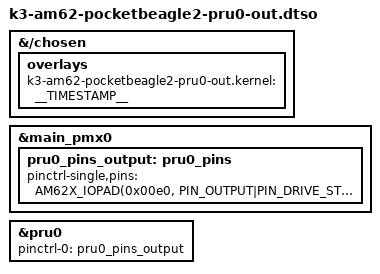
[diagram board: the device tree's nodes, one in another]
// SPDX-License-Identifier: GPL-2.0-only OR MIT
/*
 * Copyright (C) 2026 David Summers
 */
/dts-v1/;
/plugin/;

#include <dt-bindings/gpio/gpio.h>
#include "k3-pinctrl.h"

/*
 * Helper to show loaded overlays under: /proc/device-tree/chosen/overlays/
 */
&{/chosen} {
	overlays {
		k3-am62-pocketbeagle2-pru0-out.kernel = __TIMESTAMP__;
	};
};

&main_pmx0 {
	pru0_pins_output: pru0_pins {
		pinctrl-single,pins = <
			AM62X_IOPAD(0x00e0, PIN_OUTPUT|PIN_DRIVE_STRENGTH_NOMINAL, 5) /* (V20) VOUT0_DATA10.PR0_PRU0_GPO0 */
			AM62X_IOPAD(0x00e4, PIN_OUTPUT|PIN_DRIVE_STRENGTH_NOMINAL, 5) /* (AA23) VOUT0_DATA11.PR0_PRU0_GPO1 */
			AM62X_IOPAD(0x00e8, PIN_OUTPUT|PIN_DRIVE_STRENGTH_NOMINAL, 5) /* (AB25) VOUT0_DATA12.PR0_PRU0_GPO2 */
			AM62X_IOPAD(0x00ec, PIN_OUTPUT|PIN_DRIVE_STRENGTH_NOMINAL, 5) /* (AA24) VOUT0_DATA13.PR0_PRU0_GPO3 */
			AM62X_IOPAD(0x00f0, PIN_OUTPUT|PIN_DRIVE_STRENGTH_NOMINAL, 5) /* (Y22) VOUT0_DATA14.PR0_PRU0_GPO4 */
			AM62X_IOPAD(0x00f4, PIN_OUTPUT|PIN_DRIVE_STRENGTH_NOMINAL, 5) /* (AA21) VOUT0_DATA15.PR0_PRU0_GPO5 */
			AM62X_IOPAD(0x00f8, PIN_OUTPUT|PIN_DRIVE_STRENGTH_NOMINAL, 5) /* (AB24) VOUT0_HSYNC.PR0_PRU0_GPO6 */
			AM62X_IOPAD(0x00fc, PIN_OUTPUT|PIN_DRIVE_STRENGTH_NOMINAL, 5) /* (Y20) VOUT0_DE.PR0_PRU0_GPO7 */
			AM62X_IOPAD(0x00b8, PIN_OUTPUT|PIN_DRIVE_STRENGTH_NOMINAL, 5) /* (U22) VOUT0_DATA0.PR0_PRU0_GPO8 */
			AM62X_IOPAD(0x00bc, PIN_OUTPUT|PIN_DRIVE_STRENGTH_NOMINAL, 5) /* (V24) VOUT0_DATA1.PR0_PRU0_GPO9 */
			AM62X_IOPAD(0x00c0, PIN_OUTPUT|PIN_DRIVE_STRENGTH_NOMINAL, 5) /* (W25) VOUT0_DATA2.PR0_PRU0_GPO10 */
			AM62X_IOPAD(0x00c4, PIN_OUTPUT|PIN_DRIVE_STRENGTH_NOMINAL, 5) /* (W24) VOUT0_DATA3.PR0_PRU0_GPO11 */
			AM62X_IOPAD(0x00c8, PIN_OUTPUT|PIN_DRIVE_STRENGTH_NOMINAL, 5) /* (Y25) VOUT0_DATA4.PR0_PRU0_GPO12 */
			AM62X_IOPAD(0x00cc, PIN_OUTPUT|PIN_DRIVE_STRENGTH_NOMINAL, 5) /* (Y24) VOUT0_DATA5.PR0_PRU0_GPO13 */
			AM62X_IOPAD(0x00d0, PIN_OUTPUT|PIN_DRIVE_STRENGTH_NOMINAL, 5) /* (Y23) VOUT0_DATA6.PR0_PRU0_GPO14 */
			AM62X_IOPAD(0x00d4, PIN_OUTPUT|PIN_DRIVE_STRENGTH_NOMINAL, 5) /* (AA25) VOUT0_DATA7.PR0_PRU0_GPO15 */
			AM62X_IOPAD(0x00dc, PIN_OUTPUT|PIN_DRIVE_STRENGTH_NOMINAL, 5) /* (W21) VOUT0_DATA9.PR0_PRU0_GPO16 */
			AM62X_IOPAD(0x00d8, PIN_OUTPUT|PIN_DRIVE_STRENGTH_NOMINAL, 5) /* (V21) VOUT0_DATA8.PR0_PRU0_GPO17 */
			AM62X_IOPAD(0x0100, PIN_OUTPUT|PIN_DRIVE_STRENGTH_NOMINAL, 5) /* (AC25) VOUT0_VSYNC.PR0_PRU0_GPO18 */
			AM62X_IOPAD(0x0104, PIN_OUTPUT|PIN_DRIVE_STRENGTH_NOMINAL, 5) /* (AC24) VOUT0_PCLK.PR0_PRU0_GPO19 */
		>;
	};

};

&pru0 {
	pinctrl-names = "default";
	pinctrl-0 = <&pru0_pins_output>;
	status = "okay";
};
